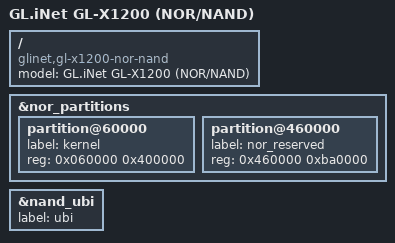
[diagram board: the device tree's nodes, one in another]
// SPDX-License-Identifier: GPL-2.0-or-later OR MIT

#include "qca9563_glinet_gl-x1200.dtsi"

/ {
	compatible = "glinet,gl-x1200-nor-nand", "qca,qca9563";
	model = "GL.iNet GL-X1200 (NOR/NAND)";
};

&nor_partitions {
	partition@60000 {
		label = "kernel";
		reg = <0x060000 0x400000>;

		/*
		 * U-Boot bootcmd is "bootm 0x9f060000".
		 * So this might be possible to resize in the future.
		 */
	};

	partition@460000 {
		label = "nor_reserved";
		reg = <0x460000 0xba0000>;
	};
};

&nand_ubi {
	label = "ubi";
};
